# R7FA4E2B9 register map
Vendor: Renesas Electronics Corporation; Series: RA4; File version: 1.40.00
CPU: CM33 r0p4, little endian, MPU, FPU, VTOR, 4 interrupt priority bits, 96 interrupts
Registers are 32-bit, read-write, reset 0x0 unless marked. A register's access mark holds for its fields unless they carry their own. Offsets are from the block's base; [hi:lo] are bit positions; 'fields as' and 'values as' point back to an identical list.

## GPT16E0 (part 1 of 2) — General PWM 16-bit Timer 0
Base 0x40169000
Same registers: GPT16E1 0x40169100, GPT16E4 0x40169400, GPT16E5 0x40169500
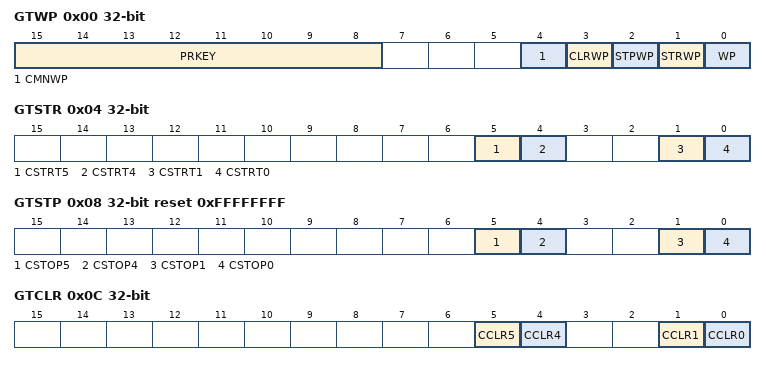
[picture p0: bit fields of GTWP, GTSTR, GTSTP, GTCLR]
0x00 GTWP — General PWM Timer Write-Protection Register
  [15:8] PRKEY wo — GTWP Key Code
  [4] CMNWP — Common Register Write Disabled
    0=Write to the register is enabled; 1=Write to the register is disabled
  [3] CLRWP — GTCLR.CCLR Bit Write Disable
    0=Write to the bit is enabled; 1=Write to the bit is disabled
  [2] STPWP — GTSTP.CSTOP Bit Write Disable
    values as CLRWP
  [1] STRWP — GTSTR.CSTRT Bit Write Disable
    values as CLRWP
  [0] WP — Register Write Disable
    0=Write to the register enabled; 1=Write to the register disabled
0x04 GTSTR — General PWM Timer Software Start Register
  [all] fields
    0=GTCNT counter not start; 1=GTCNT counter start
  [5] CSTRT5 — Channel n GTCNT Count Start (n : the same as bit position value)
  [4] CSTRT4 — Channel n GTCNT Count Start (n : the same as bit position value)
  [1] CSTRT1 — Channel n GTCNT Count Start (n : the same as bit position value)
  [0] CSTRT0 — Channel n GTCNT Count Start (n : the same as bit position value)
0x08 GTSTP reset 0xFFFFFFFF — General PWM Timer Software Stop Register
  [all] fields
    0=GTCNT counter not stop; 1=GTCNT counter stop
  [5] CSTOP5 — Channel n GTCNT Count Stop (n : the same as bit position value)
  [4] CSTOP4 — Channel n GTCNT Count Stop (n : the same as bit position value)
  [1] CSTOP1 — Channel n GTCNT Count Stop (n : the same as bit position value)
  [0] CSTOP0 — Channel n GTCNT Count Stop (n : the same as bit position value)
0x0C GTCLR wo — General PWM Timer Software Clear Register
  [all] fields
    0=GTCNT counter is not cleared; 1=GTCNT counter is cleared
  [5] CCLR5 — Channel n GTCNT Count Clear (n : the same as bit position value)
  [4] CCLR4 — Channel n GTCNT Count Clear (n : the same as bit position value)
  [1] CCLR1 — Channel n GTCNT Count Clear (n : the same as bit position value)
  [0] CCLR0 — Channel n GTCNT Count Clear (n : the same as bit position value)
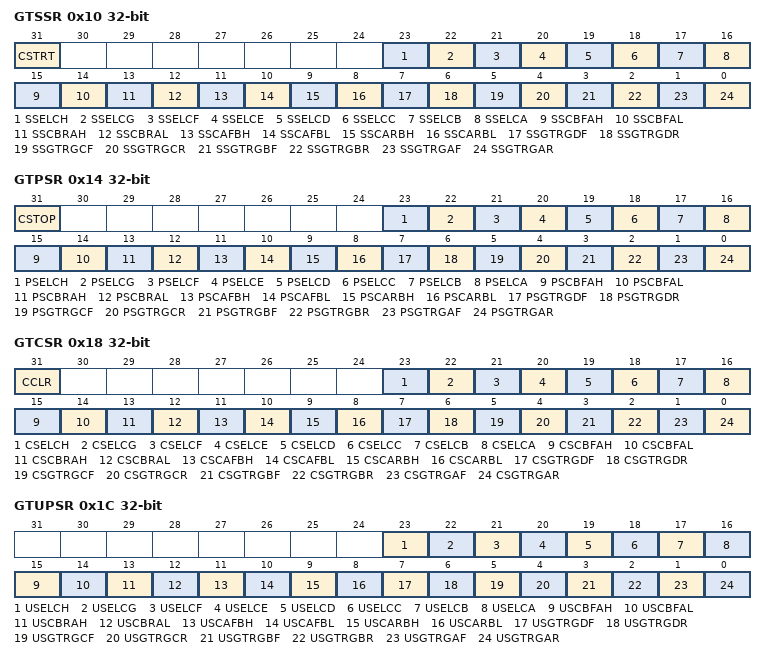
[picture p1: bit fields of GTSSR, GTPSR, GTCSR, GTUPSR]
0x10 GTSSR — General PWM Timer Start Source Select Register
  [31] CSTRT — Software Source Counter Start Enable
    0=Counter start disabled by the GTSTR register; 1=Counter start enabled by the GTSTR register
  [23] SSELCH — ELC_GPTH Event Source Counter Start Enable
    0=Counter start disabled at the ELC_GPTH input; 1=Counter start enabled at the ELC_GPTH input
  [22] SSELCG — ELC_GPTG Event Source Counter Start Enable
    0=Counter start disabled at the ELC_GPTG input; 1=Counter start enabled at the ELC_GPTG input
  [21] SSELCF — ELC_GPTF Event Source Counter Start Enable
    0=Counter start disabled at the ELC_GPTF input; 1=Counter start enabled at the ELC_GPTF input
  [20] SSELCE — ELC_GPTE Event Source Counter Start Enable
    0=Counter start disabled at the ELC_GPTE input; 1=Counter start enabled at the ELC_GPTE input
  [19] SSELCD — ELC_GPTD Event Source Counter Start Enable
    0=Counter start disabled at the ELC_GPTD input; 1=Counter start enabled at the ELC_GPTD input
  [18] SSELCC — ELC_GPTC Event Source Counter Start Enable
    0=Counter start disabled at the ELC_GPTC input; 1=Counter start enabled at the ELC_GPTC input
  [17] SSELCB — ELC_GPTB Event Source Counter Start Enable
    0=Counter start disabled at the ELC_GPTB input; 1=Counter start enabled at the ELC_GPTB input
  [16] SSELCA — ELC_GPTA Event Source Counter Start Enable
    0=Counter start disabled at the ELC_GPTA input; 1=Counter start enabled at the ELC_GPTA input
  [15] SSCBFAH — GTIOCnB Pin Falling Input during GTIOCnA Value High Source Counter Start Enable
    0=Counter start disabled on the falling edge of GTIOCnB input when GTIOCnA input is 1; 1=Counter start enabled on the falling edge of GTIOCnB input when GTIOCnA input is 1
  [14] SSCBFAL — GTIOCnB Pin Falling Input during GTIOCnA Value Low Source Counter Start Enable
    0=Counter start disabled on the falling edge of GTIOCnB input when GTIOCnA input is 0; 1=Counter start enabled on the falling edge of GTIOCnB input when GTIOCnA input is 0
  [13] SSCBRAH — GTIOCnB Pin Rising Input during GTIOCnA Value High Source Counter Start Enable
    0=Counter start disabled on the rising edge of GTIOCnB input when GTIOCnA input is 1; 1=Counter start enabled on the rising edge of GTIOCnB input when GTIOCnA input is 1
  [12] SSCBRAL — GTIOCnB Pin Rising Input during GTIOCnA Value Low Source Counter Start Enable
    0=Counter start disabled on the rising edge of GTIOCnB input when GTIOCnA input is 0; 1=Counter start enabled on the rising edge of GTIOCnB input when GTIOCnA input is 0
  [11] SSCAFBH — GTIOCnA Pin Falling Input during GTIOCnB Value High Source Counter Start Enable
    0=Counter start disabled on the falling edge of GTIOCnA input when GTIOCnB input is 1; 1=Counter start enabled on the falling edge of GTIOCnA input when GTIOCnB input is 1
  [10] SSCAFBL — GTIOCnA Pin Falling Input during GTIOCnB Value Low Source Counter Start Enable
    0=Counter start disabled on the falling edge of GTIOCnA input when GTIOCnB input is 0; 1=Counter start enabled on the falling edge of GTIOCnA input when GTIOCnB input is 0
  [9] SSCARBH — GTIOCnA Pin Rising Input during GTIOCnB Value High Source Counter Start Enable
    0=Counter start disabled on the rising edge of GTIOCnA input when GTIOCnB input is 1; 1=Counter start enabled on the rising edge of GTIOCnA input when GTIOCnB input is 1
  [8] SSCARBL — GTIOCnA Pin Rising Input during GTIOCnB Value Low Source Counter Start Enable
    0=Counter start disabled on the rising edge of GTIOCnA input when GTIOCnB input is 0; 1=Counter start enabled on the rising edge of GTIOCnA input when GTIOCnB input is 0
  [7] SSGTRGDF — GTETRGD Pin Falling Input Source Counter Start Enable
    0=Counter start disabled on the falling edge of GTETRGD input; 1=Counter start enabled on the falling edge of GTETRGD input
  [6] SSGTRGDR — GTETRGD Pin Rising Input Source Counter Start Enable
    0=Counter start disabled on the rising edge of GTETRGD input; 1=Counter start enabled on the rising edge of GTETRGD input
  [5] SSGTRGCF — GTETRGC Pin Falling Input Source Counter Start Enable
    0=Counter start disabled on the falling edge of GTETRGC input; 1=Counter start enabled on the falling edge of GTETRGC input
  [4] SSGTRGCR — GTETRGC Pin Rising Input Source Counter Start Enable
    0=Counter start disabled on the rising edge of GTETRGC input; 1=Counter start enabled on the rising edge of GTETRGC input
  [3] SSGTRGBF — GTETRGB Pin Falling Input Source Counter Start Enable
    0=Counter start disabled on the falling edge of GTETRGB input; 1=Counter start enabled on the falling edge of GTETRGB input
  [2] SSGTRGBR — GTETRGB Pin Rising Input Source Counter Start Enable
    0=Counter start disabled on the rising edge of GTETRGB input; 1=Counter start enabled on the rising edge of GTETRGB input
  [1] SSGTRGAF — GTETRGA Pin Falling Input Source Counter Start Enable
    0=Counter start disabled on the falling edge of GTETRGA input; 1=Counter start enabled on the falling edge of GTETRGA input
  [0] SSGTRGAR — GTETRGA Pin Rising Input Source Counter Start Enable
    0=Counter start disabled on the rising edge of GTETRGA input; 1=Counter start enabled on the rising edge of GTETRGA input
0x14 GTPSR — General PWM Timer Stop Source Select Register
  [31] CSTOP — Software Source Counter Stop Enable
    0=Counter stop disabled by the GTSTP register; 1=Counter stop enabled by the GTSTP register
  [23] PSELCH — ELC_GPTH Event Source Counter Stop Enable
    0=Counter stop disabled at the ELC_GPTH input; 1=Counter stop enabled at the ELC_GPTH input
  [22] PSELCG — ELC_GPTG Event Source Counter Stop Enable
    0=Counter stop disabled at the ELC_GPTG input; 1=Counter stop enabled at the ELC_GPTG input
  [21] PSELCF — ELC_GPTF Event Source Counter Stop Enable
    0=Counter stop disabled at the ELC_GPTF input; 1=Counter stop enabled at the ELC_GPTF input
  [20] PSELCE — ELC_GPTE Event Source Counter Stop Enable
    0=Counter stop disabled at the ELC_GPTE input; 1=Counter stop enabled at the ELC_GPTE input
  [19] PSELCD — ELC_GPTD Event Source Counter Stop Enable
    0=Counter stop disabled at the ELC_GPTD input; 1=Counter stop enabled at the ELC_GPTD input
  [18] PSELCC — ELC_GPTC Event Source Counter Stop Enable
    0=Counter stop disabled at the ELC_GPTC input; 1=Counter stop enabled at the ELC_GPTC input
  [17] PSELCB — ELC_GPTB Event Source Counter Stop Enable
    0=Counter stop disabled at the ELC_GPTB input; 1=Counter stop enabled at the ELC_GPTB input
  [16] PSELCA — ELC_GPTA Event Source Counter Stop Enable
    0=Counter stop disabled at the ELC_GPTA input; 1=Counter stop enabled at the ELC_GPTA input
  [15] PSCBFAH — GTIOCnB Pin Falling Input during GTIOCnA Value High Source Counter Stop Enable
    0=Counter stop disabled on the falling edge of GTIOCnB input when GTIOCnA input is 1; 1=Counter stop enabled on the falling edge of GTIOCnB input when GTIOCnA input is 1
  [14] PSCBFAL — GTIOCnB Pin Falling Input during GTIOCnA Value Low Source Counter Stop Enable
    0=Counter stop disabled on the falling edge of GTIOCnB input when GTIOCnA input is 0; 1=Counter stop enabled on the falling edge of GTIOCnB input when GTIOCnA input is 0
  [13] PSCBRAH — GTIOCnB Pin Rising Input during GTIOCnA Value High Source Counter Stop Enable
    0=Counter stop disabled on the rising edge of GTIOCnB input when GTIOCnA input is 1; 1=Counter stop enabled on the rising edge of GTIOCnB input when GTIOCnA input is 1
  [12] PSCBRAL — GTIOCnB Pin Rising Input during GTIOCnA Value Low Source Counter Stop Enable
    0=Counter stop disabled on the rising edge of GTIOCnB input when GTIOCnA input is 0; 1=Counter stop enabled on the rising edge of GTIOCnB input when GTIOCnA input is 0
  [11] PSCAFBH — GTIOCnA Pin Falling Input during GTIOCnB Value High Source Counter Stop Enable
    0=Counter stop disabled on the falling edge of GTIOCnA input when GTIOCnB input is 1; 1=Counter stop enabled on the falling edge of GTIOCnA input when GTIOCnB input is 1
  [10] PSCAFBL — GTIOCnA Pin Falling Input during GTIOCnB Value Low Source Counter Stop Enable
    0=Counter stop disabled on the falling edge of GTIOCnA input when GTIOCnB input is 0; 1=Counter stop enabled on the falling edge of GTIOCnA input when GTIOCnB input is 0
  [9] PSCARBH — GTIOCnA Pin Rising Input during GTIOCnB Value High Source Counter Stop Enable
    0=Counter stop disabled on the rising edge of GTIOCnA input when GTIOCnB input is 1; 1=Counter stop enabled on the rising edge of GTIOCnA input when GTIOCnB input is 1
  [8] PSCARBL — GTIOCnA Pin Rising Input during GTIOCnB Value Low Source Counter Stop Enable
    0=Counter stop disabled on the rising edge of GTIOCnA input when GTIOCnB input is 0; 1=Counter stop enabled on the rising edge of GTIOCnA input when GTIOCnB input is 0
  [7] PSGTRGDF — GTETRGD Pin Falling Input Source Counter Stop Enable
    0=Counter stop disabled on the falling edge of GTETRGD input; 1=Counter stop enabled on the falling edge of GTETRGD input
  [6] PSGTRGDR — GTETRGD Pin Rising Input Source Counter Stop Enable
    0=Counter stop disabled on the rising edge of GTETRGD input; 1=Counter stop enabled on the rising edge of GTETRGD input
  [5] PSGTRGCF — GTETRGC Pin Falling Input Source Counter Stop Enable
    0=Counter stop disabled on the falling edge of GTETRGC input; 1=Counter stop enabled on the falling edge of GTETRGC input
  [4] PSGTRGCR — GTETRGC Pin Rising Input Source Counter Stop Enable
    0=Counter stop disabled on the rising edge of GTETRGC input; 1=Counter stop enabled on the rising edge of GTETRGC input
  [3] PSGTRGBF — GTETRGB Pin Falling Input Source Counter Stop Enable
    0=Counter stop disabled on the falling edge of GTETRGB input; 1=Counter stop enabled on the falling edge of GTETRGB input
  [2] PSGTRGBR — GTETRGB Pin Rising Input Source Counter Stop Enable
    0=Counter stop disabled on the rising edge of GTETRGB input; 1=Counter stop enabled on the rising edge of GTETRGB input
  [1] PSGTRGAF — GTETRGA Pin Falling Input Source Counter Stop Enable
    0=Counter stop disabled on the falling edge of GTETRGA input; 1=Counter stop enabled on the falling edge of GTETRGA input
  [0] PSGTRGAR — GTETRGA Pin Rising Input Source Counter Stop Enable
    0=Counter stop disabled on the rising edge of GTETRGA input; 1=Counter stop enabled on the rising edge of GTETRGA input
0x18 GTCSR — General PWM Timer Clear Source Select Register
  [31] CCLR — Software Source Counter Clear Enable
    0=Counter clear disabled by the GTCLR register; 1=Counter clear enabled by the GTCLR register
  [23] CSELCH — ELC_GPTH Event Source Counter Clear Enable
    0=Counter clear disabled at the ELC_GPTH input; 1=Counter clear enabled at the ELC_GPTH input
  [22] CSELCG — ELC_GPTG Event Source Counter Clear Enable
    0=Counter clear disabled at the ELC_GPTG input; 1=Counter clear enabled at the ELC_GPTG input
  [21] CSELCF — ELC_GPTF Event Source Counter Clear Enable
    0=Counter clear disabled at the ELC_GPTF input; 1=Counter clear enabled at the ELC_GPTF input
  [20] CSELCE — ELC_GPTE Event Source Counter Clear Enable
    0=Counter clear disabled at the ELC_GPTE input; 1=Counter clear enabled at the ELC_GPTE input
  [19] CSELCD — ELC_GPTD Event Source Counter Clear Enable
    0=Counter clear disabled at the ELC_GPTD input; 1=Counter clear enabled at the ELC_GPTD input
  [18] CSELCC — ELC_GPTC Event Source Counter Clear Enable
    0=Counter clear disabled at the ELC_GPTC input; 1=Counter clear enabled at the ELC_GPTC input
  [17] CSELCB — ELC_GPTB Event Source Counter Clear Enable
    0=Counter clear disabled at the ELC_GPTB input; 1=Counter clear enabled at the ELC_GPTB input
  [16] CSELCA — ELC_GPTA Event Source Counter Clear Enable
    0=Counter clear disabled at the ELC_GPTA input; 1=Counter clear enabled at the ELC_GPTA input
  [15] CSCBFAH — GTIOCnB Pin Falling Input during GTIOCnA Value High Source Counter Clear Enable
    0=Counter clear disabled on the falling edge of GTIOCnB input when GTIOCnA input is 1; 1=Counter clear enabled on the falling edge of GTIOCnB input when GTIOCnA input is 1
  [14] CSCBFAL — GTIOCnB Pin Falling Input during GTIOCnA Value Low Source Counter Clear Enable
    0=Counter clear disabled on the falling edge of GTIOCnB input when GTIOCnA input is 0; 1=Counter clear enabled on the falling edge of GTIOCnB input when GTIOCnA input is 0
  [13] CSCBRAH — GTIOCnB Pin Rising Input during GTIOCnA Value High Source Counter Clear Enable
    0=Counter clear disabled on the rising edge of GTIOCnB input when GTIOCnA input is 1; 1=Counter clear enabled on the rising edge of GTIOCnB input when GTIOCnA input is 1
  [12] CSCBRAL — GTIOCnB Pin Rising Input during GTIOCnA Value Low Source Counter Clear Enable
    0=Counter clear disabled on the rising edge of GTIOCnB input when GTIOCnA input is 0; 1=Counter clear enabled on the rising edge of GTIOCnB input when GTIOCnA input is 0
  [11] CSCAFBH — GTIOCnA Pin Falling Input during GTIOCnB Value High Source Counter Clear Enable
    0=Counter clear disabled on the falling edge of GTIOCnA input when GTIOCnB input is 1; 1=Counter clear enabled on the falling edge of GTIOCnA input when GTIOCnB input is 1
  [10] CSCAFBL — GTIOCnA Pin Falling Input during GTIOCnB Value Low Source Counter Clear Enable
    0=Counter clear disabled on the falling edge of GTIOCnA input when GTIOCnB input is 0; 1=Counter clear enabled on the falling edge of GTIOCnA input when GTIOCnB input is 0
  [9] CSCARBH — GTIOCnA Pin Rising Input during GTIOCnB Value High Source Counter Clear Enable
    0=Counter clear disabled on the rising edge of GTIOCnA input when GTIOCnB input is 1; 1=Counter clear enabled on the rising edge of GTIOCnA input when GTIOCnB input is 1
  [8] CSCARBL — GTIOCnA Pin Rising Input during GTIOCnB Value Low Source Counter Clear Enable
    0=Counter clear disabled on the rising edge of GTIOCnA input when GTIOCnB input is 0; 1=Counter clear enabled on the rising edge of GTIOCnA input when GTIOCnB input is 0
  [7] CSGTRGDF — GTETRGD Pin Falling Input Source Counter Clear Enable
    0=Counter clear disabled on the falling edge of GTETRGD input; 1=Counter clear enabled on the falling edge of GTETRGD input
  [6] CSGTRGDR — GTETRGD Pin Rising Input Source Counter Clear Enable
    0=Disable counter clear on the rising edge of GTETRGD input; 1=Enable counter clear on the rising edge of GTETRGD input
  [5] CSGTRGCF — GTETRGC Pin Falling Input Source Counter Clear Enable
    0=Counter clear disabled on the falling edge of GTETRGC input; 1=Counter clear enabled on the falling edge of GTETRGC input
  [4] CSGTRGCR — GTETRGC Pin Rising Input Source Counter Clear Enable
    0=Disable counter clear on the rising edge of GTETRGC input; 1=Enable counter clear on the rising edge of GTETRGC input
  [3] CSGTRGBF — GTETRGB Pin Falling Input Source Counter Clear Enable
    0=Counter clear disabled on the falling edge of GTETRGB input; 1=Counter clear enabled on the falling edge of GTETRGB input
  [2] CSGTRGBR — GTETRGB Pin Rising Input Source Counter Clear Enable
    0=Disable counter clear on the rising edge of GTETRGB input; 1=Enable counter clear on the rising edge of GTETRGB input
  [1] CSGTRGAF — GTETRGA Pin Falling Input Source Counter Clear Enable
    0=Counter clear disabled on the falling edge of GTETRGA input; 1=Counter clear enabled on the falling edge of GTETRGA input
  [0] CSGTRGAR — GTETRGA Pin Rising Input Source Counter Clear Enable
    0=Counter clear disabled on the rising edge of GTETRGA input; 1=Counter clear enabled on the rising edge of GTETRGA input
0x1C GTUPSR — General PWM Timer Up Count Source Select Register
  [23] USELCH — ELC_GPTH Event Source Counter Count Up Enable
    0=Counter count up disabled at the ELC_GPTH input; 1=Counter count up enabled at the ELC_GPTH input
  [22] USELCG — ELC_GPTG Event Source Counter Count Up Enable
    0=Counter count up disabled at the ELC_GPTG input; 1=Counter count up enabled at the ELC_GPTG input
  [21] USELCF — ELC_GPTF Event Source Counter Count Up Enable
    0=Counter count up disabled at the ELC_GPTF input; 1=Counter count up enabled at the ELC_GPTF input
  [20] USELCE — ELC_GPTE Event Source Counter Count Up Enable
    0=Counter count up disabled at the ELC_GPTE input; 1=Counter count up enabled at the ELC_GPTE input
  [19] USELCD — ELC_GPTD Event Source Counter Count Up Enable
    0=Counter count up disabled at the ELC_GPTD input; 1=Counter count up enabled at the ELC_GPTD input
  [18] USELCC — ELC_GPTC Event Source Counter Count Up Enable
    0=Counter count up disabled at the ELC_GPTC input; 1=Counter count up enabled at the ELC_GPTC input
  [17] USELCB — ELC_GPTB Event Source Counter Count Up Enable
    0=Counter count up disabled at the ELC_GPTB input; 1=Counter count up enabled at the ELC_GPTB input
  [16] USELCA — ELC_GPTA Event Source Counter Count Up Enable
    0=Counter count up disabled at the ELC_GPTA input; 1=Counter count up enabled at the ELC_GPTA input
  [15] USCBFAH — GTIOCnB Pin Falling Input during GTIOCnA Value High Source Counter Count Up Enable
    0=Counter count up disabled on the falling edge of GTIOCnB input when GTIOCnA input is 1; 1=Counter count up enabled on the falling edge of GTIOCnB input when GTIOCnA input is 1
  [14] USCBFAL — GTIOCnB Pin Falling Input during GTIOCnA Value Low Source Counter Count Up Enable
    0=Counter count up disabled on the falling edge of GTIOCnB input when GTIOCnA input is 0; 1=Counter count up enabled on the falling edge of GTIOCnB input when GTIOCnA input is 0
  [13] USCBRAH — GTIOCnB Pin Rising Input during GTIOCnA Value High Source Counter Count Up Enable
    0=Counter count up disabled on the rising edge of GTIOCnB input when GTIOCnA input is 1; 1=Counter count up enabled on the rising edge of GTIOCnB input when GTIOCnA input is 1
  [12] USCBRAL — GTIOCnB Pin Rising Input during GTIOCnA Value Low Source Counter Count Up Enable
    0=Counter count up disabled on the rising edge of GTIOCnB input when GTIOCnA input is 0; 1=Counter count up enabled on the rising edge of GTIOCnB input when GTIOCnA input is 0
  [11] USCAFBH — GTIOCnA Pin Falling Input during GTIOCnB Value High Source Counter Count Up Enable
    0=Counter count up disabled on the falling edge of GTIOCnA input when GTIOCnB input is 1; 1=Counter count up enabled on the falling edge of GTIOCnA input when GTIOCnB input is 1
  [10] USCAFBL — GTIOCnA Pin Falling Input during GTIOCnB Value Low Source Counter Count Up Enable
    0=Counter count up disabled on the falling edge of GTIOCnA input when GTIOCnB input is 0; 1=Counter count up enabled on the falling edge of GTIOCnA input when GTIOCnB input is 0
  [9] USCARBH — GTIOCnA Pin Rising Input during GTIOCnB Value High Source Counter Count Up Enable
    0=Counter count up disabled on the rising edge of GTIOCnA input when GTIOCnB input is 1; 1=Counter count up enabled on the rising edge of GTIOCnA input when GTIOCnB input is 1
  [8] USCARBL — GTIOCnA Pin Rising Input during GTIOCnB Value Low Source Counter Count Up Enable
    0=Counter count up disabled on the rising edge of GTIOCnA input when GTIOCnB input is 0; 1=Counter count up enabled on the rising edge of GTIOCnA input when GTIOCnB input is 0
  [7] USGTRGDF — GTETRGD Pin Falling Input Source Counter Count Up Enable
    0=Counter count up disabled on the falling edge of GTETRGD input; 1=Counter count up enabled on the falling edge of GTETRGD input
  [6] USGTRGDR — GTETRGD Pin Rising Input Source Counter Count Up Enable
    0=Counter count up disabled on the rising edge of GTETRGD input; 1=Counter count up enabled on the rising edge of GTETRGD input
  [5] USGTRGCF — GTETRGC Pin Falling Input Source Counter Count Up Enable
    0=Counter count up disabled on the falling edge of GTETRGC input; 1=Counter count up enabled on the falling edge of GTETRGC input
  [4] USGTRGCR — GTETRGC Pin Rising Input Source Counter Count Up Enable
    0=Counter count up disabled on the rising edge of GTETRGC input; 1=Counter count up enabled on the rising edge of GTETRGC input
  [3] USGTRGBF — GTETRGB Pin Falling Input Source Counter Count Up Enable
    0=Counter count up disabled on the falling edge of GTETRGB input; 1=Counter count up enabled on the falling edge of GTETRGB input
  [2] USGTRGBR — GTETRGB Pin Rising Input Source Counter Count Up Enable
    0=Counter count up disabled on the rising edge of GTETRGB input; 1=Counter count up enabled on the rising edge of GTETRGB input
  [1] USGTRGAF — GTETRGA Pin Falling Input Source Counter Count Up Enable
    0=Counter count up disabled on the falling edge of GTETRGA input; 1=Counter count up enabled on the falling edge of GTETRGA input
  [0] USGTRGAR — GTETRGA Pin Rising Input Source Counter Count Up Enable
    0=Counter count up disabled on the rising edge of GTETRGA input; 1=Counter count up enabled on the rising edge of GTETRGA input
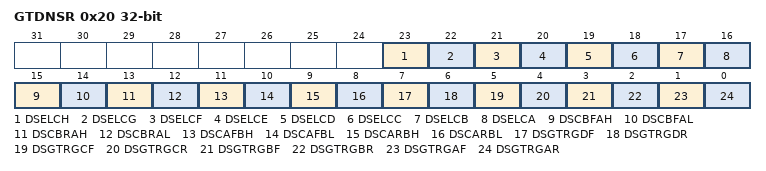
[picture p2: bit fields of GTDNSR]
0x20 GTDNSR — General PWM Timer Down Count Source Select Register
  [23] DSELCH — ELC_GPTH Event Source Counter Count Down Enable
    0=Counter count down disabled at the ELC_GPTH input; 1=Counter count down enabled at the ELC_GPTH input
  [22] DSELCG — ELC_GPTG Event Source Counter Count Down Enable
    0=Counter count down disabled at the ELC_GPTG input; 1=Counter count down enabled at the ELC_GPTG input
  [21] DSELCF — ELC_GPTF Event Source Counter Count Down Enable
    0=Counter count down disabled at the ELC_GPTF input; 1=Counter count down enabled at the ELC_GPTF input
  [20] DSELCE — ELC_GPTE Event Source Counter Count Down Enable
    0=Counter count down disabled at the ELC_GPTE input; 1=Counter count down enabled at the ELC_GPTE input
  [19] DSELCD — ELC_GPTD Event Source Counter Count Down Enable
    0=Counter count down disabled at the ELC_GPTD input; 1=Counter count down enabled at the ELC_GPTD input
  [18] DSELCC — ELC_GPTC Event Source Counter Count Down Enable
    0=Counter count down disabled at the ELC_GPTC input; 1=Counter count down enabled at the ELC_GPTC input
  [17] DSELCB — ELC_GPTB Event Source Counter Count Down Enable
    0=Counter count down disabled at the ELC_GPTB input; 1=Counter count down enabled at the ELC_GPTB input
  [16] DSELCA — ELC_GPTA Event Source Counter Count Down Enable
    0=Counter count down disabled at the ELC_GPTA input; 1=Counter count down enabled at the ELC_GPTA input
  [15] DSCBFAH — GTIOCnB Pin Falling Input during GTIOCnA Value High Source Counter Count Down Enable
    0=Counter count down disabled on the falling edge of GTIOCnB input when GTIOCnA input is 1; 1=Counter count down enabled on the falling edge of GTIOCnB input when GTIOCnA input is 1
  [14] DSCBFAL — GTIOCnB Pin Falling Input during GTIOCnA Value Low Source Counter Count Down Enable
    0=Counter count down disabled on the falling edge of GTIOCnB input when GTIOCnA input is 0; 1=Counter count down enabled on the falling edge of GTIOCnB input when GTIOCnA input is 0
  [13] DSCBRAH — GTIOCnB Pin Rising Input during GTIOCnA Value High Source Counter Count Down Enable
    0=Counter count down disabled on the rising edge of GTIOCnB input when GTIOCnA input is 1; 1=Counter count down enabled on the rising edge of GTIOCnB input when GTIOCnA input is 1
  [12] DSCBRAL — GTIOCnB Pin Rising Input during GTIOCnA Value Low Source Counter Count Down Enable
    0=Counter count down disabled on the rising edge of GTIOCnB input when GTIOCnA input is 0; 1=Counter count down enabled on the rising edge of GTIOCnB input when GTIOCnA input is 0
  [11] DSCAFBH — GTIOCnA Pin Falling Input during GTIOCnB Value High Source Counter Count Down Enable
    0=Counter count down disabled on the falling edge of GTIOCnA input when GTIOCnB input is 1; 1=Counter count down enabled on the falling edge of GTIOCnA input when GTIOCnB input is 1
  [10] DSCAFBL — GTIOCnA Pin Falling Input during GTIOCnB Value Low Source Counter Count Down Enable
    0=Counter count down disabled on the falling edge of GTIOCnA input when GTIOCnB input is 0; 1=Counter count down enabled on the falling edge of GTIOCnA input when GTIOCnB input is 0
  [9] DSCARBH — GTIOCnA Pin Rising Input during GTIOCnB Value High Source Counter Count Down Enable
    0=Counter count down disabled on the rising edge of GTIOCnA input when GTIOCnB input is 1; 1=Counter count down enabled on the rising edge of GTIOCnA input when GTIOCnB input is 1
  [8] DSCARBL — GTIOCnA Pin Rising Input during GTIOCnB Value Low Source Counter Count Down Enable
    0=Counter count down disabled on the rising edge of GTIOCnA input when GTIOCnB input is 0; 1=Counter count down enabled on the rising edge of GTIOCnA input when GTIOCnB input is 0
  [7] DSGTRGDF — GTETRGD Pin Falling Input Source Counter Count Down Enable
    0=Counter count down disabled on the falling edge of GTETRGD input; 1=Counter count down enabled on the falling edge of GTETRGD input
  [6] DSGTRGDR — GTETRGD Pin Rising Input Source Counter Count Down Enable
    0=Counter count down disabled on the rising edge of GTETRGD input; 1=Counter count down enabled on the rising edge of GTETRGD input
  [5] DSGTRGCF — GTETRGC Pin Falling Input Source Counter Count Down Enable
    0=Counter count down disabled on the falling edge of GTETRGC input; 1=Counter count down enabled on the falling edge of GTETRGC input
  [4] DSGTRGCR — GTETRGC Pin Rising Input Source Counter Count Down Enable
    0=Counter count down disabled on the rising edge of GTETRGC input; 1=Counter count down enabled on the rising edge of GTETRGC input
  [3] DSGTRGBF — GTETRGB Pin Falling Input Source Counter Count Down Enable
    0=Counter count down disabled on the falling edge of GTETRGB input; 1=Counter count down enabled on the falling edge of GTETRGB input
  [2] DSGTRGBR — GTETRGB Pin Rising Input Source Counter Count Down Enable
    0=Counter count down disabled on the rising edge of GTETRGB input; 1=Counter count down enabled on the rising edge of GTETRGB input
  [1] DSGTRGAF — GTETRGA Pin Falling Input Source Counter Count Down Enable
    0=Counter count down disabled on the falling edge of GTETRGA input; 1=Counter count down enabled on the falling edge of GTETRGA input
  [0] DSGTRGAR — GTETRGA Pin Rising Input Source Counter Count Down Enable
    0=Counter count down disabled on the rising edge of GTETRGA input; 1=Counter count down enabled on the rising edge of GTETRGA input
